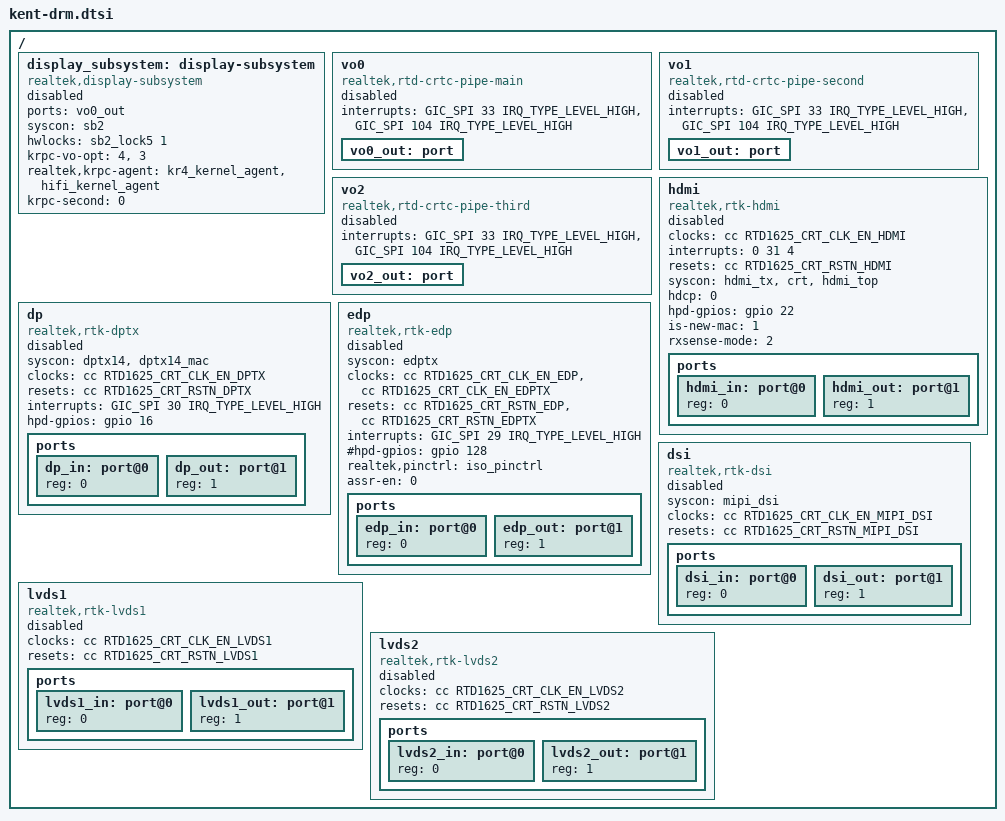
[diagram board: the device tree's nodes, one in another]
// SPDX-License-Identifier: (GPL-2.0-or-later OR BSD-2-Clause)
/*
 * Copyright (c) 2024 Realtek Semiconductor Corp.
 */

/* PLEASE include this file inside a node */
/ {
	display_subsystem: display-subsystem {
		compatible = "realtek,display-subsystem";
		ports = <&vo0_out>;
		syscon = <&sb2>;
		hwlocks = <&sb2_lock5 1>;
		krpc-vo-opt = <4>, <3>;
		realtek,krpc-agent = <&kr4_kernel_agent>, <&hifi_kernel_agent>;
		krpc-second = <0>;
		status = "disabled";
	};

	vo0: vo0 {
		compatible = "realtek,rtd-crtc-pipe-main";
		interrupts = <GIC_SPI 33 IRQ_TYPE_LEVEL_HIGH>,
					<GIC_SPI 104 IRQ_TYPE_LEVEL_HIGH>;
		status = "disabled";

		vo0_out: port {
		};
	};

	vo1: vo1 {
		compatible = "realtek,rtd-crtc-pipe-second";
		interrupts = <GIC_SPI 33 IRQ_TYPE_LEVEL_HIGH>,
					<GIC_SPI 104 IRQ_TYPE_LEVEL_HIGH>;
		status = "disabled";

		vo1_out: port {
		};
	};

	vo2: vo2 {
		compatible = "realtek,rtd-crtc-pipe-third";
		interrupts = <GIC_SPI 33 IRQ_TYPE_LEVEL_HIGH>,
					<GIC_SPI 104 IRQ_TYPE_LEVEL_HIGH>;
		status = "disabled";

		vo2_out: port {
		};
	};

	hdmi: hdmi {
		compatible = "realtek,rtk-hdmi";
		clock-names = "clk_en_hdmi";
		clocks = <&cc RTD1625_CRT_CLK_EN_HDMI>;
		interrupts = <0 31 4>; /* RxSense */
		reset-names = "rstn_hdmi";
		resets = <&cc RTD1625_CRT_RSTN_HDMI>;
		syscon = <&hdmi_tx>, <&crt>, <&hdmi_top>;
		hdcp = <0>;
		hpd-gpios = <&gpio 22 GPIO_PULL_DOWN>;
		is-new-mac = <1>;
		rxsense-mode = <2>;
		status = "disabled";

		ports {
			#address-cells = <1>;
			#size-cells = <0>;

			hdmi_in: port@0 {
				reg = <0>;
			};

			hdmi_out: port@1 {
				reg = <1>;
			};
		};
	};

	dp: dp {
		compatible = "realtek,rtk-dptx";
		syscon = <&dptx14>, <&dptx14_mac>;
		clock-names = "clk_en_dptx";
		clocks = <&cc RTD1625_CRT_CLK_EN_DPTX>;
		reset-names = "rstn_dptx";
		resets = <&cc RTD1625_CRT_RSTN_DPTX>;
		interrupts = <GIC_SPI 30 IRQ_TYPE_LEVEL_HIGH>;
		hpd-gpios = <&gpio 16 GPIO_PULL_DOWN>;
		status = "disabled";

		ports {
			#address-cells = <1>;
			#size-cells = <0>;

			dp_in: port@0 {
				reg = <0>;
			};

			dp_out: port@1 {
				reg = <1>;
			};
		};
	};

	edp: edp {
		compatible = "realtek,rtk-edp";
		syscon = <&edptx>;
		clock-names = "clk_en_edp", "clk_en_edptx";
		clocks = <&cc RTD1625_CRT_CLK_EN_EDP>,
				<&cc RTD1625_CRT_CLK_EN_EDPTX>;
		reset-names = "rstn_edp", "rstn_edptx";
		resets = <&cc RTD1625_CRT_RSTN_EDP>,
				<&cc RTD1625_CRT_RSTN_EDPTX>;
		interrupts = <GIC_SPI 29 IRQ_TYPE_LEVEL_HIGH>;
		#hpd-gpios = <&gpio 128 GPIO_PULL_DOWN>;
		realtek,pinctrl = <&iso_pinctrl>;
		assr-en = <0>;
		status = "disabled";

		ports {
			#address-cells = <1>;
			#size-cells = <0>;

			edp_in: port@0 {
				reg = <0>;
			};

			edp_out: port@1 {
				reg = <1>;
			};
		};
	};

	dsi: dsi {
		compatible = "realtek,rtk-dsi";
		syscon = <&mipi_dsi>;
		clocks = <&cc RTD1625_CRT_CLK_EN_MIPI_DSI>;
		clock-names = "clk_en_dsi";
		resets = <&cc RTD1625_CRT_RSTN_MIPI_DSI>;
		reset-names = "dsi";
		status = "disabled";

		ports {
			#address-cells = <1>;
			#size-cells = <0>;

			dsi_in: port@0 {
				reg = <0>;
			};

			dsi_out: port@1 {
				reg = <1>;
			};
		};
	};

	lvds1: lvds1 {
		compatible = "realtek,rtk-lvds1";
		clock-names = "clk_en_lvds1";
		clocks = <&cc RTD1625_CRT_CLK_EN_LVDS1>;
		reset-names = "rstn_lvds1";
		resets = <&cc RTD1625_CRT_RSTN_LVDS1>;

		status = "disabled";

		ports {
			#address-cells = <1>;
			#size-cells = <0>;

			lvds1_in: port@0 {
				reg = <0>;
			};

			lvds1_out: port@1 {
				reg = <1>;
			};
		};
	};

	lvds2: lvds2 {
		compatible = "realtek,rtk-lvds2";
		clock-names = "clk_en_lvds2";
		clocks = <&cc RTD1625_CRT_CLK_EN_LVDS2>;
		reset-names = "rstn_lvds2";
		resets = <&cc RTD1625_CRT_RSTN_LVDS2>;

		status = "disabled";

		ports {
			#address-cells = <1>;
			#size-cells = <0>;

			lvds2_in: port@0 {
				reg = <0>;
			};

			lvds2_out: port@1 {
				reg = <1>;
			};
		};
	};
};
